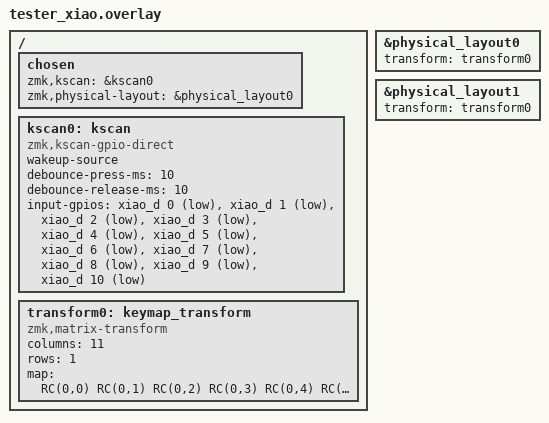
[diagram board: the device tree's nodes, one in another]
#include <dt-bindings/zmk/matrix_transform.h>
#include "tester_xiao-layouts.dtsi"

&physical_layout0 {
    transform = <&transform0>;
};

&physical_layout1 {
    transform = <&transform0>;
};

/ {
    chosen {
        zmk,kscan = &kscan0;
        zmk,physical-layout = &physical_layout0;
    };

    kscan0: kscan {
        compatible = "zmk,kscan-gpio-direct";
        wakeup-source;
        debounce-press-ms = <10>;
        debounce-release-ms = <10>;
        input-gpios
            = <&xiao_d 0 (GPIO_ACTIVE_LOW | GPIO_PULL_UP)>
            , <&xiao_d 1 (GPIO_ACTIVE_LOW | GPIO_PULL_UP)>
            , <&xiao_d 2 (GPIO_ACTIVE_LOW | GPIO_PULL_UP)>
            , <&xiao_d 3 (GPIO_ACTIVE_LOW | GPIO_PULL_UP)>
            , <&xiao_d 4 (GPIO_ACTIVE_LOW | GPIO_PULL_UP)>
            , <&xiao_d 5 (GPIO_ACTIVE_LOW | GPIO_PULL_UP)>
            , <&xiao_d 6 (GPIO_ACTIVE_LOW | GPIO_PULL_UP)>
            , <&xiao_d 7 (GPIO_ACTIVE_LOW | GPIO_PULL_UP)>
            , <&xiao_d 8 (GPIO_ACTIVE_LOW | GPIO_PULL_UP)>
            , <&xiao_d 9 (GPIO_ACTIVE_LOW | GPIO_PULL_UP)>
            , <&xiao_d 10 (GPIO_ACTIVE_LOW | GPIO_PULL_UP)>
            ;
    };

    transform0: keymap_transform {
        compatible = "zmk,matrix-transform";
        columns = <11>;
        rows = <1>;
        map = <
        RC(0,0)  RC(0,1)  RC(0,2)  RC(0,3)  RC(0,4)  RC(0,5)  RC(0,6)  RC(0,7)  RC(0,8)  RC(0,9)  RC(0,10)
        >;
    };
};
